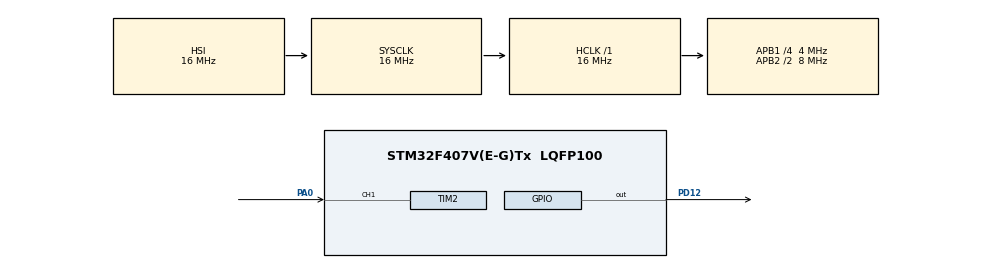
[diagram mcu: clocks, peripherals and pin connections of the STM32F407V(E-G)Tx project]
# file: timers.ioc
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Mcu.Family=STM32F4
Mcu.Name=STM32F407V(E-G)Tx
Mcu.Package=LQFP100
NVIC.PriorityGroup=NVIC_PRIORITYGROUP_4
NVIC.TIM2_IRQn=true\:0\:0\:false\:false\:true\:true
PA0-WKUP.Signal=S_TIM2_CH1_ETR
PD12.Signal=GPIO_Output
PH0-OSC_IN.Mode=HSE-External-Oscillator
PH0-OSC_IN.Signal=RCC_OSC_IN
PH1-OSC_OUT.Mode=HSE-External-Oscillator
PH1-OSC_OUT.Signal=RCC_OSC_OUT
ProjectManager.HeapSize=0x200
ProjectManager.StackSize=0x400
ProjectManager.TargetToolchain=TrueSTUDIO
RCC.48MHZClocksFreq_Value=168000000
RCC.AHBFreq_Value=16000000
RCC.APB1CLKDivider=RCC_HCLK_DIV4
RCC.APB1Freq_Value=4000000
RCC.APB1TimFreq_Value=8000000
RCC.APB2CLKDivider=RCC_HCLK_DIV2
RCC.APB2Freq_Value=8000000
RCC.APB2TimFreq_Value=16000000
RCC.CortexFreq_Value=16000000
RCC.HCLKFreq_Value=16000000
RCC.HSE_VALUE=8000000
RCC.HSI_VALUE=16000000
RCC.LSE_VALUE=32768
RCC.PLLM=4
RCC.PLLN=168
RCC.SYSCLKFreq_VALUE=16000000
RCC.VCOOutputFreq_Value=672000000
SH.S_TIM2_CH1_ETR.0=TIM2_CH1,Input_Capture1_from_TI1
TIM2.Channel-Input_Capture1_from_TI1=TIM_CHANNEL_1
TIM2.ICFilter_CH1=15
TIM2.Period=1000
TIM2.Prescaler=8
VP_TIM2_VS_ClockSourceINT.Mode=Internal
board=timers

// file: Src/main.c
/**
  ******************************************************************************
  * File Name          : main.c
  * Description        : Main program body
  ******************************************************************************
  ** This notice applies to any and all portions of this file
  * that are not between comment pairs USER CODE BEGIN and
  * USER CODE END. Other portions of this file, whether
  * inserted by the user or by software development tools
  * are owned by their respective copyright owners.
  *
  * COPYRIGHT(c) 2018 STMicroelectronics
  *
  * Redistribution and use in source and binary forms, with or without modification,
  * are permitted provided that the following conditions are met:
  *   1. Redistributions of source code must retain the above copyright notice,
  *      this list of conditions and the following disclaimer.
  *   2. Redistributions in binary form must reproduce the above copyright notice,
  *      this list of conditions and the following disclaimer in the documentation
  *      and/or other materials provided with the distribution.
  *   3. Neither the name of STMicroelectronics nor the names of its contributors
  *      may be used to endorse or promote products derived from this software
  *      without specific prior written permission.
  *
  * THIS SOFTWARE IS PROVIDED BY THE COPYRIGHT HOLDERS AND CONTRIBUTORS "AS IS"
  * AND ANY EXPRESS OR IMPLIED WARRANTIES, INCLUDING, BUT NOT LIMITED TO, THE
  * IMPLIED WARRANTIES OF MERCHANTABILITY AND FITNESS FOR A PARTICULAR PURPOSE ARE
  * DISCLAIMED. IN NO EVENT SHALL THE COPYRIGHT HOLDER OR CONTRIBUTORS BE LIABLE
  * FOR ANY DIRECT, INDIRECT, INCIDENTAL, SPECIAL, EXEMPLARY, OR CONSEQUENTIAL
  * DAMAGES (INCLUDING, BUT NOT LIMITED TO, PROCUREMENT OF SUBSTITUTE GOODS OR
  * SERVICES; LOSS OF USE, DATA, OR PROFITS; OR BUSINESS INTERRUPTION) HOWEVER
  * CAUSED AND ON ANY THEORY OF LIABILITY, WHETHER IN CONTRACT, STRICT LIABILITY,
  * OR TORT (INCLUDING NEGLIGENCE OR OTHERWISE) ARISING IN ANY WAY OUT OF THE USE
  * OF THIS SOFTWARE, EVEN IF ADVISED OF THE POSSIBILITY OF SUCH DAMAGE.
  *
  ******************************************************************************
  */

#include "main.h"
#include "stm32f4xx_hal.h"

TIM_HandleTypeDef htim2;

/* USER CODE BEGIN PV */
/* Private variables ---------------------------------------------------------*/

/* USER CODE END PV */

void SystemClock_Config(void);
static void MX_GPIO_Init(void);
static void MX_TIM2_Init(void);

/* USER CODE BEGIN PFP */
/* Private function prototypes -----------------------------------------------*/

/* USER CODE END PFP */

/* USER CODE BEGIN 0 */

void delay(uint32_t delayCount)
{
	volatile uint32_t i;
	for(i=0;i<delayCount;i++);
}

#if(0)
void DutyGenerator(GPIO_TypeDef* GPIOx, uint16_t GPIO_Pin,uint8_t v_dutyCycle_u8,uint16_t V_timePeriod_u16)
{
  uint16_t v_tOn_u16, v_tOff_u16;
  v_tOn_u16 = (v_dutyCycle_u8 * V_timePeriod_u16) / 100;
  v_tOff_u16 = (V_timePeriod_u16 - v_tOn_u16 );
  assert_param(IS_GPIO_PIN(GPIO_Pin));
  HAL_GPIO_WritePin(GPIOx,GPIO_Pin,GPIO_PIN_SET);
  delay(v_tOn_u16);
  HAL_GPIO_WritePin(GPIOx,GPIO_Pin,GPIO_PIN_RESET);
  delay(v_tOff_u16);

}
#endif

void HAL_TIM_PeriodElapsedCallback(TIM_HandleTypeDef *htim)
{

	if(htim->Instance == TIM2)
	{
		HAL_GPIO_TogglePin(GPIOD,GPIO_PIN_12);
	}
}
/* USER CODE END 0 */
uint16_t cnt =1000;
int main(void)
{

  /* MCU Configuration----------------------------------------------------------*/

  /* Reset of all peripherals, Initializes the Flash interface and the Systick. */
  HAL_Init();

  /* Configure the system clock */
  SystemClock_Config();

  /* Initialize all configured peripherals */
  MX_GPIO_Init();
  MX_TIM2_Init();

  /* USER CODE BEGIN 2 */

  HAL_TIM_Base_Start_IT(&htim2);

  /* USER CODE END 2 */

  /* Infinite loop */
  while (1)
  {

	  cnt=500;
	  __HAL_TIM_SET_AUTORELOAD(&htim2,cnt);
  }

}

/** System Clock Configuration
*/
void SystemClock_Config(void)
{

  RCC_OscInitTypeDef RCC_OscInitStruct;
  RCC_ClkInitTypeDef RCC_ClkInitStruct;

    /**Configure the main internal regulator output voltage
    */
  __HAL_RCC_PWR_CLK_ENABLE();

  __HAL_PWR_VOLTAGESCALING_CONFIG(PWR_REGULATOR_VOLTAGE_SCALE1);

    /**Initializes the CPU, AHB and APB busses clocks
    */
  RCC_OscInitStruct.OscillatorType = RCC_OSCILLATORTYPE_HSI;
  RCC_OscInitStruct.HSIState = RCC_HSI_ON;
  RCC_OscInitStruct.HSICalibrationValue = 16;
  RCC_OscInitStruct.PLL.PLLState = RCC_PLL_NONE;
  if (HAL_RCC_OscConfig(&RCC_OscInitStruct) != HAL_OK)
  {
    _Error_Handler(__FILE__, __LINE__);
  }

    /**Initializes the CPU, AHB and APB busses clocks
    */
  RCC_ClkInitStruct.ClockType = RCC_CLOCKTYPE_HCLK|RCC_CLOCKTYPE_SYSCLK
                              |RCC_CLOCKTYPE_PCLK1|RCC_CLOCKTYPE_PCLK2;
  RCC_ClkInitStruct.SYSCLKSource = RCC_SYSCLKSOURCE_HSI;
  RCC_ClkInitStruct.AHBCLKDivider = RCC_SYSCLK_DIV1;
  RCC_ClkInitStruct.APB1CLKDivider = RCC_HCLK_DIV4;
  RCC_ClkInitStruct.APB2CLKDivider = RCC_HCLK_DIV2;

  if (HAL_RCC_ClockConfig(&RCC_ClkInitStruct, FLASH_LATENCY_0) != HAL_OK)
  {
    _Error_Handler(__FILE__, __LINE__);
  }

    /**Configure the Systick interrupt time
    */
  HAL_SYSTICK_Config(HAL_RCC_GetHCLKFreq()/1000);

    /**Configure the Systick
    */
  HAL_SYSTICK_CLKSourceConfig(SYSTICK_CLKSOURCE_HCLK);

  /* SysTick_IRQn interrupt configuration */
  HAL_NVIC_SetPriority(SysTick_IRQn, 0, 0);
}

/* TIM2 init function */
static void MX_TIM2_Init(void)
{

  TIM_ClockConfigTypeDef sClockSourceConfig;
  TIM_MasterConfigTypeDef sMasterConfig;
  TIM_IC_InitTypeDef sConfigIC;

  htim2.Instance = TIM2;
  htim2.Init.Prescaler = 8;
  htim2.Init.CounterMode = TIM_COUNTERMODE_UP;
  htim2.Init.Period = 1000;
  htim2.Init.ClockDivision = TIM_CLOCKDIVISION_DIV1;
  if (HAL_TIM_Base_Init(&htim2) != HAL_OK)
  {
    _Error_Handler(__FILE__, __LINE__);
  }

  sClockSourceConfig.ClockSource = TIM_CLOCKSOURCE_INTERNAL;
  if (HAL_TIM_ConfigClockSource(&htim2, &sClockSourceConfig) != HAL_OK)
  {
    _Error_Handler(__FILE__, __LINE__);
  }

  if (HAL_TIM_IC_Init(&htim2) != HAL_OK)
  {
    _Error_Handler(__FILE__, __LINE__);
  }

  sMasterConfig.MasterOutputTrigger = TIM_TRGO_RESET;
  sMasterConfig.MasterSlaveMode = TIM_MASTERSLAVEMODE_DISABLE;
  if (HAL_TIMEx_MasterConfigSynchronization(&htim2, &sMasterConfig) != HAL_OK)
  {
    _Error_Handler(__FILE__, __LINE__);
  }

  sConfigIC.ICPolarity = TIM_INPUTCHANNELPOLARITY_RISING;
  sConfigIC.ICSelection = TIM_ICSELECTION_DIRECTTI;
  sConfigIC.ICPrescaler = TIM_ICPSC_DIV1;
  sConfigIC.ICFilter = 15;
  if (HAL_TIM_IC_ConfigChannel(&htim2, &sConfigIC, TIM_CHANNEL_1) != HAL_OK)
  {
    _Error_Handler(__FILE__, __LINE__);
  }

}

/** Configure pins as
        * Analog
        * Input
        * Output
        * EVENT_OUT
        * EXTI
*/
static void MX_GPIO_Init(void)
{

  GPIO_InitTypeDef GPIO_InitStruct;

  /* GPIO Ports Clock Enable */
  __HAL_RCC_GPIOH_CLK_ENABLE();
  __HAL_RCC_GPIOA_CLK_ENABLE();
  __HAL_RCC_GPIOD_CLK_ENABLE();

  /*Configure GPIO pin Output Level */
  HAL_GPIO_WritePin(GPIOD, GPIO_PIN_12, GPIO_PIN_RESET);

  /*Configure GPIO pin : PD12 */
  GPIO_InitStruct.Pin = GPIO_PIN_12;
  GPIO_InitStruct.Mode = GPIO_MODE_OUTPUT_PP;
  GPIO_InitStruct.Pull = GPIO_NOPULL;
  GPIO_InitStruct.Speed = GPIO_SPEED_FREQ_LOW;
  HAL_GPIO_Init(GPIOD, &GPIO_InitStruct);

}

void _Error_Handler(char * file, int line)
{
  while(1)
  {
  }
}

/************************ (C) COPYRIGHT STMicroelectronics *****END OF FILE****/
